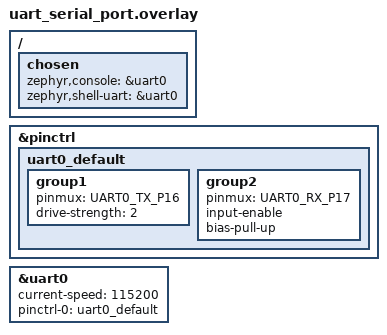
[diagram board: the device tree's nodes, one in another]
/* SPDX-License-Identifier: Apache-2.0
 * Copyright (c) 2025 Blue Vending
 */

/ {
	chosen {
		zephyr,console = &uart0;
		zephyr,shell-uart = &uart0;
	};
};

/* UART0 configuration for console and logging on GP16 (TX) and GP17 (RX) */
&pinctrl {
	uart0_default: uart0_default {
		group1 {
			pinmux = <UART0_TX_P16>;
			drive-strength = <2>;
		};
		group2 {
			pinmux = <UART0_RX_P17>;
			input-enable;
			bias-pull-up;
		};
	};
};

&uart0 {
	status = "okay";
	current-speed = <115200>;
	pinctrl-0 = <&uart0_default>;
	pinctrl-names = "default";
};
